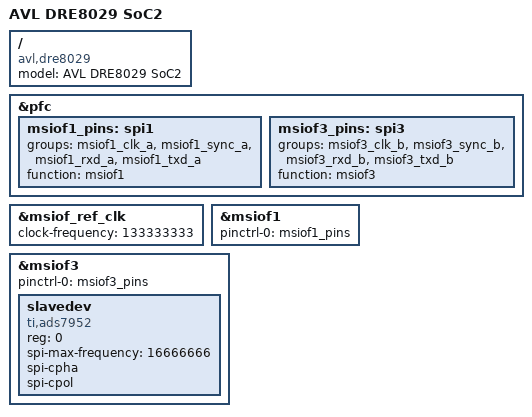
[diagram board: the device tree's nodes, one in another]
/*
 * Device Tree Source for the Salvator-X.View board
 *
 * Copyright (C) 2016-2019 Renesas Electronics Corp.
 *
 * This file is licensed under the terms of the GNU General Public License
 * version 2.  This program is licensed "as is" without any warranty of any
 * kind, whether express or implied.
 */

/dts-v1/;

#include "common-AVL-DRE8029.dtsi"

/ {
	model = "AVL DRE8029 SoC2";
	compatible = "avl,dre8029", "renesas,r8a7795";
};

&pfc {
    msiof1_pins: spi1 {
        groups = "msiof1_clk_a", "msiof1_sync_a",
        "msiof1_rxd_a", "msiof1_txd_a";
        function = "msiof1";
    };

    msiof3_pins: spi3 {
        groups = "msiof3_clk_b", "msiof3_sync_b",
        "msiof3_rxd_b", "msiof3_txd_b";
        function = "msiof3";
    };
};

/* module clock */
&msiof_ref_clk {
    clock-frequency = <133333333>;
};

&msiof1 {
    pinctrl-0 = <&msiof1_pins>;
    pinctrl-names = "default";

    /* status = "okay"; */

    /* Add a subnode. */
};

&msiof3 {
    pinctrl-0 = <&msiof3_pins>;
    pinctrl-names = "default";

    status = "okay";

	slavedev {
        compatible = "ti,ads7952";
		reg = <0>;
		spi-max-frequency = <16666666>;
		spi-cpha;
		spi-cpol;
    };
};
